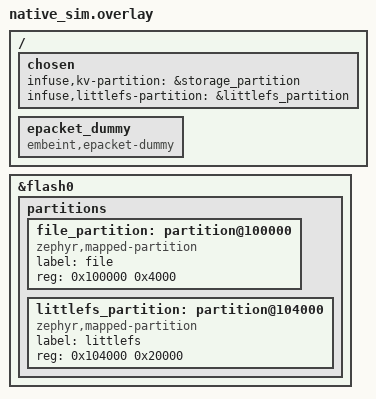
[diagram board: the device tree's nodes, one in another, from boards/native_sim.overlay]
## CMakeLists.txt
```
# SPDX-License-Identifier: Apache-2.0

cmake_minimum_required(VERSION 3.20.0)

# Infuse-IoT application
if(NOT infuse IN_LIST SNIPPET)
  set(SNIPPET infuse ${SNIPPET} CACHE STRING "" FORCE)
endif()

find_package(Zephyr REQUIRED HINTS $ENV{ZEPHYR_BASE})
project(rpc_commands_coap_download)

target_sources(app PRIVATE
  src/main.c
)
```

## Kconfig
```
config TEST_NATIVE_MOCK
	bool "Mock various file backends"
	default y if BOARD_NATIVE_SIM

config BT_CONTROLLER_MANAGER
	default y if TEST_NATIVE_MOCK

config TEST_COAP_SERVER
	string "CoAP server to download test resources from"
	default "coap.dev.infuse-iot.com"

config TEST_COAP_SERVER_PORT
	int "CoAP server DTLS port"
	default 5684

config TEST_COAP_SERVER_UNRESPONSIVE
	string "Server that resolves but never completes a DTLS handshake"
	default "www.google.com"

source "Kconfig.zephyr"
```

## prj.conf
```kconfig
CONFIG_ZTEST=y
CONFIG_INFUSE_SDK=y
CONFIG_INFUSE_CPATCH=y
CONFIG_INFUSE_DFU_HELPERS=y
CONFIG_INFUSE_RPC_LOG_LEVEL_DBG=y

CONFIG_NETWORKING=y

# Drop received packets to exercise the retry logic
CONFIG_INFUSE_COAP_TEST_PACKET_DROP_BITMASK=16389
```

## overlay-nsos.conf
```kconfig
CONFIG_ETH_NATIVE_POSIX=n
CONFIG_NET_DRIVERS=y
CONFIG_NET_SOCKETS=y
CONFIG_NET_SOCKETS_OFFLOAD=y
CONFIG_NET_NATIVE_OFFLOADED_SOCKETS=y
CONFIG_HEAP_MEM_POOL_SIZE=1024

CONFIG_NATIVE_SIM_SLOWDOWN_TO_REAL_TIME=y
```

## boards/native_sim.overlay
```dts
/ {
	chosen {
		infuse,kv-partition = &storage_partition;
		infuse,littlefs-partition = &littlefs_partition;
	};

	epacket_dummy: epacket_dummy {
		compatible = "embeint,epacket-dummy";
	};
};

&flash0 {
	partitions {
		file_partition: partition@100000 {
			compatible = "zephyr,mapped-partition";
			label = "file";
			reg = < 0x100000 0x4000 >;
		};
		littlefs_partition: partition@104000 {
			compatible = "zephyr,mapped-partition";
			label = "littlefs";
			reg = < 0x104000 0x20000 >;
		};
	};
};
```

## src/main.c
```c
/**
 * @file
 * @copyright 2024 Embeint Holdings Pty Ltd
 * @author Jordan Yates <jordan@embeint.com>
 *
 * SPDX-License-Identifier: FSL-1.1-ALv2
 */

#include <string.h>

#include <zephyr/ztest.h>
#include <zephyr/random/random.h>
#include <zephyr/storage/flash_map.h>
#include <zephyr/net/tls_credentials.h>
#include <zephyr/sys/crc.h>

#include <infuse/dfu/helpers.h>
#include <infuse/security.h>
#include <infuse/common_boot.h>
#include <infuse/types.h>
#include <infuse/rpc/types.h>
#include <infuse/rpc/errors.h>
#include <infuse/epacket/packet.h>
#include <infuse/epacket/interface/epacket_dummy.h>
#include <infuse/time/epoch.h>
#include <infuse/fs/littlefs.h>

#define COAP_SERVER              CONFIG_TEST_COAP_SERVER
#define COAP_PORT                CONFIG_TEST_COAP_SERVER_PORT
#define COAP_SERVER_UNRESPONSIVE CONFIG_TEST_COAP_SERVER_UNRESPONSIVE

struct rpc_coap_download_request_send {
	struct rpc_coap_download_request core;
	char resource[128];
} __packed;

struct rpc_coap_download_request_v2_send {
	struct rpc_coap_download_v2_request core;
	char resource[128];
} __packed;

struct rpc_coap_download_request_v3_send {
	struct rpc_coap_download_v3_request core;
	char resource[128];
} __packed;

#ifdef CONFIG_TLS_CREDENTIALS
/* Buffer must remain valid after `tls_credential_add` */
static char dtls_identity_buffer[16];
#endif /* CONFIG_TLS_CREDENTIALS */

#ifdef CONFIG_TEST_NATIVE_MOCK
static size_t bt_image_len;
static size_t bt_image_crc;
static uint32_t bt_fail_after;
static bool bt_in_progress;
static int bt_start_rc;
static int bt_finish_rc;

int bt_controller_manager_file_write_start(uint32_t *ctx, uint8_t action, size_t image_len)
{
	bt_image_len = image_len;
	bt_image_crc = 0;
	if (bt_start_rc == 0) {
		bt_in_progress = true;
	}
	return bt_start_rc;
}

int bt_controller_manager_file_write_next(uint32_t ctx, uint32_t image_offset,
					  const void *image_chunk, size_t chunk_len)
{
	zassert_equal(0, image_offset % sizeof(uint32_t));

	bt_image_crc = crc32_ieee_update(bt_image_crc, image_chunk, chunk_len);

	if (bt_fail_after > 0) {
		if (--bt_fail_after == 0) {
			return -EIO;
		}
	}
	return 0;
}

int bt_controller_manager_file_write_finish(uint32_t ctx, uint32_t *len, uint32_t *crc)
{
	*len = bt_image_len;
	*crc = bt_image_crc;
	bt_in_progress = false;
	return bt_finish_rc;
}

#endif /* CONFIG_TEST_NATIVE_MOCK */

static void send_download_command(uint32_t request_id, const char *server, uint16_t port,
				  uint16_t timeout, uint8_t action, char *resource, uint32_t len,
				  uint32_t crc)
{
	const struct device *epacket_dummy = DEVICE_DT_GET(DT_NODELABEL(epacket_dummy));
	struct epacket_dummy_frame header = {
		.type = INFUSE_RPC_CMD,
		.auth = EPACKET_AUTH_DEVICE,
		.flags = 0x0000,
	};
	struct rpc_coap_download_request_send params = {
		.core = {
			.header =
				{
					.request_id = request_id,
					.command_id = RPC_ID_COAP_DOWNLOAD,
				},
			.server_port = port,
			.block_timeout_ms = timeout,
			.action = action,
			.resource_crc = crc,
			.resource_len = len,
		}};

	strncpy(params.core.server_address, server, sizeof(params.core.server_address));
	params.core.server_port = port;
	strncpy(params.resource, resource, sizeof(params.resource));

	/* Push command at RPC server */
	epacket_dummy_receive(epacket_dummy, &header, &params, sizeof(params));
}

static void send_download_v2_command(uint32_t request_id, const char *server, uint16_t port,
				     uint16_t timeout, uint8_t action, char *resource, uint32_t len,
				     uint32_t crc, uint16_t block_size)
{
	const struct device *epacket_dummy = DEVICE_DT_GET(DT_NODELABEL(epacket_dummy));
	struct epacket_dummy_frame header = {
		.type = INFUSE_RPC_CMD,
		.auth = EPACKET_AUTH_DEVICE,
		.flags = 0x0000,
	};
	struct rpc_coap_download_request_v2_send params = {
		.core = {
			.header =
				{
					.request_id = request_id,
					.command_id = RPC_ID_COAP_DOWNLOAD_V2,
				},
			.server_port = port,
			.block_timeout_ms = timeout,
			.block_size = block_size,
			.action = action,
			.resource_crc = crc,
			.resource_len = len,
		}};

	strncpy(params.core.server_address, server, sizeof(params.core.server_address));
	params.core.server_port = port;
	strncpy(params.resource, resource, sizeof(params.resource));

	/* Push command at RPC server */
	epacket_dummy_receive(epacket_dummy, &header, &params, sizeof(params));
}

static void send_download_v3_command(uint32_t request_id, const char *server, uint16_t port,
				     uint16_t timeout, uint8_t action, uint8_t folder,
				     uint32_t filename, uint32_t identifier, char *resource,
				     uint32_t len, uint32_t crc, uint16_t block_size)
{
	const struct device *epacket_dummy = DEVICE_DT_GET(DT_NODELABEL(epacket_dummy));
	struct epacket_dummy_frame header = {
		.type = INFUSE_RPC_CMD,
		.auth = EPACKET_AUTH_DEVICE,
		.flags = 0x0000,
	};
	struct rpc_coap_download_request_v3_send params = {
		.core = {
			.header =
				{
					.request_id = request_id,
					.command_id = RPC_ID_COAP_DOWNLOAD_V3,
				},
			.server_port = port,
			.block_timeout_ms = timeout,
			.block_size = block_size,
			.action = action,
			.folder = folder,
			.filename = filename,
			.identifier = identifier,
			.resource_crc = crc,
			.resource_len = len,
		}};

	strncpy(params.core.server_address, server, sizeof(params.core.server_address));
	params.core.server_port = port;
	strncpy(params.resource, resource, sizeof(params.resource));

	/* Push command at RPC server */
	epacket_dummy_receive(epacket_dummy, &header, &params, sizeof(params));
}

static void expect_coap_download_response(uint32_t request_id, int16_t rc, uint32_t len,
					  uint32_t crc)
{
	struct k_fifo *response_queue = epacket_dummmy_transmit_fifo_get();
	struct rpc_coap_download_response *response;
	struct net_buf *rsp;

	zassert_not_null(response_queue);

	/* Response was sent */
	rsp = k_fifo_get(response_queue, K_SECONDS(30));
	zassert_not_null(rsp);
	response = (void *)(rsp->data + sizeof(struct epacket_dummy_frame));

	/* Parameters match what we expect */
	zassert_equal(request_id, response->header.request_id);
	zassert_equal(rc, response->header.return_code);
	zassert_equal(len, response->resource_len);
	zassert_equal(crc, response->resource_crc);

	/* Free the response */
	net_buf_unref(rsp);
}

static void send_download_v3_raw(uint32_t request_id, bool terminate_server,
				 bool terminate_resource)
{
	const struct device *epacket_dummy = DEVICE_DT_GET(DT_NODELABEL(epacket_dummy));
	struct epacket_dummy_frame header = {
		.type = INFUSE_RPC_CMD,
		.auth = EPACKET_AUTH_DEVICE,
		.flags = 0x0000,
	};
	struct rpc_coap_download_request_v3_send params = {
		.core = {
			.header =
				{
					.request_id = request_id,
					.command_id = RPC_ID_COAP_DOWNLOAD_V3,
				},
			.server_port = COAP_PORT,
			.action = RPC_ENUM_FILE_ACTION_DISCARD,
			.resource_crc = UINT32_MAX,
			.resource_len = UINT32_MAX,
		}};
	size_t resource_len;

	if (terminate_server) {
		strcpy(params.core.server_address, COAP_SERVER);
	} else {
		memset(params.core.server_address, 's', sizeof(params.core.server_address));
	}

	if (terminate_resource) {
		strcpy(params.resource, "file/small_file");
		resource_len = strlen(params.resource) + 1;
	} else {
		memset(params.resource, 'r', sizeof(params.resource));
		resource_len = sizeof(params.resource);
	}

	epacket_dummy_receive(epacket_dummy, &header, &params, sizeof(params.core) + resource_len);
}

ZTEST(rpc_command_coap_download, test_download_invalid_strings)
{
	send_download_v3_raw(0x5000, false, true);
	expect_coap_download_response(0x5000, INFUSE_RPC_ERROR_MALFORMED_REQUEST, 0, 0);

	send_download_v3_raw(0x5001, true, false);
	expect_coap_download_response(0x5001, INFUSE_RPC_ERROR_MALFORMED_REQUEST, 0, 0);
}

ZTEST(rpc_command_coap_download, test_download_invalid)
{
	/* Bad actions */
	send_download_command(1, COAP_SERVER, COAP_PORT, 0, 5, "file/small", UINT32_MAX,
			      UINT32_MAX);
	expect_coap_download_response(1, INFUSE_RPC_ERROR_UNSUPPORTED_REQUEST, 0, 0);
	send_download_command(2, COAP_SERVER, COAP_PORT, 0, 5, "file/small", UINT32_MAX,
			      UINT32_MAX);
	expect_coap_download_response(2, INFUSE_RPC_ERROR_UNSUPPORTED_REQUEST, 0, 0);

	/* Bad file */
	send_download_command(5, COAP_SERVER, COAP_PORT, 0, RPC_ENUM_FILE_ACTION_DISCARD,
			      "file/doesn't-exist", UINT32_MAX, UINT32_MAX);
	expect_coap_download_response(5, INFUSE_RPC_ERROR_COAP_DOWNLOAD_FAILED, 0, 0);

	/* Bad server */
	send_download_command(3, "does-not-exist.invalid", COAP_PORT, 0,
			      RPC_ENUM_FILE_ACTION_DISCARD, "file/small", UINT32_MAX, UINT32_MAX);
	expect_coap_download_response(3, INFUSE_RPC_ERROR_DNS_QUERY_FAILED, 0, 0);

	/* Bad port */
	send_download_command(4, COAP_SERVER, 1000, 0, RPC_ENUM_FILE_ACTION_DISCARD, "file/small",
			      UINT32_MAX, UINT32_MAX);
	expect_coap_download_response(4, INFUSE_RPC_ERROR_SOCKET_CONNECT_FAILED, 0, 0);

	/* Connect failure */
	send_download_command(6, COAP_SERVER_UNRESPONSIVE, COAP_PORT, 0,
			      RPC_ENUM_FILE_ACTION_DISCARD, "file/small", UINT32_MAX, UINT32_MAX);
	expect_coap_download_response(6, INFUSE_RPC_ERROR_SOCKET_CONNECT_FAILED, 0, 0);

	/* Tiny timeout */
	send_download_command(20, COAP_SERVER, COAP_PORT, 1, RPC_ENUM_FILE_ACTION_DISCARD,
			      "file/small_file", UINT32_MAX, UINT32_MAX);
	expect_coap_download_response(20, INFUSE_RPC_ERROR_COAP_DOWNLOAD_FAILED, 0, 0);

#ifdef CONFIG_TLS_CREDENTIALS
	sec_tag_t tag = infuse_security_coap_dtls_tag();
	size_t cred_len;

	/* Cache the credential */
	cred_len = sizeof(dtls_identity_buffer);
	zassert_equal(
		0, tls_credential_get(tag, TLS_CREDENTIAL_PSK_ID, dtls_identity_buffer, &cred_len));
	zassert_equal(sizeof(dtls_identity_buffer), cred_len);

	/* Delete the credential */
	zassert_equal(0, tls_credential_delete(tag, TLS_CREDENTIAL_PSK_ID));

	/* Basic discard download */
	send_download_command(100, COAP_SERVER, COAP_PORT, 0, RPC_ENUM_FILE_ACTION_DISCARD,
			      "file/small_file", UINT32_MAX, UINT32_MAX);
	expect_coap_download_response(100, INFUSE_RPC_ERROR_SOCKET_CONFIG_FAILED, 0, 0);

	/* Re-add the credential */
	zassert_equal(0, tls_credential_add(tag, TLS_CREDENTIAL_PSK_ID, dtls_identity_buffer,
					    sizeof(dtls_identity_buffer)));
#endif /* CONFIG_TLS_CREDENTIALS */

	/* Everything works after all the failures */
	send_download_command(10, COAP_SERVER, COAP_PORT, 0, RPC_ENUM_FILE_ACTION_DISCARD,
			      "file/small_file", UINT32_MAX, UINT32_MAX);
	expect_coap_download_response(10, 0, 12, 0xb5289bef);
}

ZTEST(rpc_command_coap_download, test_download)
{
	const struct flash_area *fa;

	/* Ensure consistent starting point */
	flash_area_open(PARTITION_ID(slot1_partition), &fa);
	flash_area_erase(fa, 0, fa->fa_size);
	flash_area_close(fa);

	/* Basic discard download */
	send_download_command(10, COAP_SERVER, COAP_PORT, 0, RPC_ENUM_FILE_ACTION_DISCARD,
			      "file/small_file", UINT32_MAX, UINT32_MAX);
	expect_coap_download_response(10, 0, 12, 0xb5289bef);

	/* Larger discard download */
	send_download_command(10, COAP_SERVER, COAP_PORT, 0, RPC_ENUM_FILE_ACTION_DISCARD,
			      "file/med_file", UINT32_MAX, UINT32_MAX);
	expect_coap_download_response(10, 0, 10030, 0x9919d24e);

	/* Small DFU download of unknown length and size */
	send_download_command(20, COAP_SERVER, COAP_PORT, 0, RPC_ENUM_FILE_ACTION_APP_IMG,
			      "file/small_file", UINT32_MAX, UINT32_MAX);
	expect_coap_download_response(20, 0, 12, 0xb5289bef);

	/* Download file contents for DFU */
	send_download_command(10, COAP_SERVER, COAP_PORT, 0, RPC_ENUM_FILE_ACTION_APP_IMG,
			      "file/med_file", 10030, 0x9919d24e);
	expect_coap_download_response(10, 0, 10030, 0x9919d24e);

	/* Second time should detect file has already been downloaded */
	send_download_command(11, COAP_SERVER, COAP_PORT, 0, RPC_ENUM_FILE_ACTION_APP_IMG,
			      "file/med_file", 10030, 0x9919d24e);
	expect_coap_download_response(11, 0, 0, 0x9919d24e);

	/* But if CRC not provided, file is downloaded again */
	send_download_command(12, COAP_SERVER, COAP_PORT, 0, RPC_ENUM_FILE_ACTION_APP_IMG,
			      "file/med_file", 10030, UINT32_MAX);
	expect_coap_download_response(12, 0, 10030, 0x9919d24e);

	/* DFU requested too large */
	send_download_command(20, COAP_SERVER, COAP_PORT, 0, RPC_ENUM_FILE_ACTION_APP_IMG,
			      "file/small_file", UINT32_MAX / 2, UINT32_MAX);
	expect_coap_download_response(20, INFUSE_RPC_ERROR_FLASH_DATA_TOO_LARGE, 0, 0);

	/* Balanced call count */
	zassert_equal(0, infuse_dfu_write_erase_call_count());
}

ZTEST(rpc_command_coap_download, test_download_v2)
{
	/* Basic discard download */
	send_download_v2_command(48, COAP_SERVER, COAP_PORT, 0, RPC_ENUM_FILE_ACTION_DISCARD,
				 "file/small_file", UINT32_MAX, UINT32_MAX, 0);
	expect_coap_download_response(48, 0, 12, 0xb5289bef);

	/* Larger discard download */
	send_download_v2_command(50, COAP_SERVER, COAP_PORT, 0, RPC_ENUM_FILE_ACTION_DISCARD,
				 "file/med_file", UINT32_MAX, UINT32_MAX, 1024);
	expect_coap_download_response(50, 0, 10030, 0x9919d24e);
}

ZTEST(rpc_command_coap_download, test_download_v3)
{
	struct infuse_littlefs_metadata meta;
	int rc;

	/* Basic discard download */
	send_download_v3_command(200, COAP_SERVER, COAP_PORT, 0, RPC_ENUM_FILE_ACTION_DISCARD, 0, 0,
				 0, "file/small_file", UINT32_MAX, UINT32_MAX, 0);
	expect_coap_download_response(200, 0, 12, 0xb5289bef);

	/* Larger discard download */
	send_download_v3_command(201, COAP_SERVER, COAP_PORT, 0, RPC_ENUM_FILE_ACTION_DISCARD, 0, 0,
				 0, "file/med_file", UINT32_MAX, UINT32_MAX, 1024);
	expect_coap_download_response(201, 0, 10030, 0x9919d24e);

	/* Write an algorithm */
	send_download_v3_command(202, COAP_SERVER, COAP_PORT, 0,
				 RPC_ENUM_FILE_ACTION_WRITE_LITTLEFS, INFUSE_LFS_FOLDER_ALGORITHMS,
				 0, 1000, "file/small_file", 12, 0xb5289bef, 512);
	expect_coap_download_response(202, 0, 12, 0xb5289bef);
	rc = infuse_littlefs_file_size(INFUSE_LFS_FOLDER_ALGORITHMS, 0);
	zassert_equal(12, rc);
	rc = infuse_littlefs_file_metadata(INFUSE_LFS_FOLDER_ALGORITHMS, 0, &meta);
	zassert_equal(0, rc);
	zassert_equal(1000, meta.identifier);
	zassert_equal(0xb5289bef, meta.crc);

	/* Same algorithm again doesn't download data */
	send_download_v3_command(203, COAP_SERVER, COAP_PORT, 0,
				 RPC_ENUM_FILE_ACTION_WRITE_LITTLEFS, INFUSE_LFS_FOLDER_ALGORITHMS,
				 0, 1000, "file/small_file", 12, 0xb5289bef, 512);
	expect_coap_download_response(203, 0, 0, 0xb5289bef);
	rc = infuse_littlefs_file_size(INFUSE_LFS_FOLDER_ALGORITHMS, 0);
	zassert_equal(12, rc);
	rc = infuse_littlefs_file_metadata(INFUSE_LFS_FOLDER_ALGORITHMS, 0, &meta);
	zassert_equal(0, rc);
	zassert_equal(1000, meta.identifier);
	zassert_equal(0xb5289bef, meta.crc);

	/* Different algorithm to same slot overwrites */
	send_download_v3_command(204, COAP_SERVER, COAP_PORT, 0,
				 RPC_ENUM_FILE_ACTION_WRITE_LITTLEFS, INFUSE_LFS_FOLDER_ALGORITHMS,
				 0, 1001, "file/med_file", 10030, 0x9919d24e, 1024);
	expect_coap_download_response(204, 0, 10030, 0x9919d24e);
	rc = infuse_littlefs_file_size(INFUSE_LFS_FOLDER_ALGORITHMS, 0);
	zassert_equal(10030, rc);
	rc = infuse_littlefs_file_metadata(INFUSE_LFS_FOLDER_ALGORITHMS, 0, &meta);
	zassert_equal(0, rc);
	zassert_equal(1001, meta.identifier);
	zassert_equal(0x9919d24e, meta.crc);

	/* Different algorithm */
	send_download_v3_command(205, COAP_SERVER, COAP_PORT, 0,
				 RPC_ENUM_FILE_ACTION_WRITE_LITTLEFS, INFUSE_LFS_FOLDER_ALGORITHMS,
				 5, 0x200, "file/small_file", 12, 0xb5289bef, 0);
	expect_coap_download_response(205, 0, 12, 0xb5289bef);
	rc = infuse_littlefs_file_size(INFUSE_LFS_FOLDER_ALGORITHMS, 5);
	zassert_equal(12, rc);
	rc = infuse_littlefs_file_metadata(INFUSE_LFS_FOLDER_ALGORITHMS, 5, &meta);
	zassert_equal(0, rc);
	zassert_equal(0x200, meta.identifier);
	zassert_equal(0xb5289bef, meta.crc);

	/* Non-algorithm folder */
	send_download_v3_command(206, COAP_SERVER, COAP_PORT, 0,
				 RPC_ENUM_FILE_ACTION_WRITE_LITTLEFS, INFUSE_LFS_FOLDER_COPY, 100,
				 0x201, "file/small_file", 12, 0xb5289bef, 0);
	expect_coap_download_response(206, 0, 12, 0xb5289bef);
	rc = infuse_littlefs_file_size(INFUSE_LFS_FOLDER_COPY, 100);
	zassert_equal(12, rc);
	rc = infuse_littlefs_file_metadata(INFUSE_LFS_FOLDER_COPY, 100, &meta);
	zassert_equal(0, rc);
	zassert_equal(0x201, meta.identifier);
	zassert_equal(0xb5289bef, meta.crc);
}

ZTEST(rpc_command_coap_download, test_download_v3_error_cleanup)
{
	struct infuse_littlefs_metadata meta;
	int rc;

	/* Download request that will immediately timeout, file should be closed, but not deleted */
	send_download_v3_command(20, COAP_SERVER, COAP_PORT, 1, RPC_ENUM_FILE_ACTION_WRITE_LITTLEFS,
				 INFUSE_LFS_FOLDER_ALGORITHMS, 0, 1001, "file/med_file", 10030,
				 0x9919d24e, 1024);
	expect_coap_download_response(20, INFUSE_RPC_ERROR_COAP_DOWNLOAD_FAILED, 0, 0);
	rc = infuse_littlefs_file_size(INFUSE_LFS_FOLDER_ALGORITHMS, 0);
	zassert_equal(0, rc);
	rc = infuse_littlefs_file_metadata(INFUSE_LFS_FOLDER_ALGORITHMS, 0, &meta);
	zassert_equal(0, rc);
	zassert_equal(1001, meta.identifier);
	zassert_equal(0, meta.crc);
}

ZTEST(rpc_command_coap_download, test_download_littlefs_reject)
{
	/* ACTION_WRITE_LITTLEFS should be rejected for legacy RPCs */
	send_download_command(99, COAP_SERVER, COAP_PORT, 0, RPC_ENUM_FILE_ACTION_WRITE_LITTLEFS,
			      "file/small_file", UINT32_MAX, UINT32_MAX);
	expect_coap_download_response(99, INFUSE_RPC_ERROR_UNSUPPORTED_REQUEST, 0, 0);

	send_download_v2_command(100, COAP_SERVER, COAP_PORT, 0,
				 RPC_ENUM_FILE_ACTION_WRITE_LITTLEFS, "file/small_file", UINT32_MAX,
				 UINT32_MAX, 0);
	expect_coap_download_response(100, INFUSE_RPC_ERROR_UNSUPPORTED_REQUEST, 0, 0);
}

ZTEST(rpc_command_coap_download, test_download_bt_ctlr)
{
#ifdef CONFIG_TEST_NATIVE_MOCK
	send_download_command(15, COAP_SERVER, COAP_PORT, 0, RPC_ENUM_FILE_ACTION_BT_CTLR_IMG,
			      "file/med_file", 10030, UINT32_MAX);
	expect_coap_download_response(15, 0, 10030, 0x9919d24e);
	zassert_false(bt_in_progress);

	bt_start_rc = -EIO;
	send_download_command(20, COAP_SERVER, COAP_PORT, 0, RPC_ENUM_FILE_ACTION_BT_CTLR_IMG,
			      "file/med_file", 10030, UINT32_MAX);
	expect_coap_download_response(20, INFUSE_RPC_ERROR_BT_COMMAND_QUEUE_FAILED, 0, 0);
	zassert_false(bt_in_progress);
	bt_start_rc = 0;

	bt_fail_after = 10;
	send_download_command(16, COAP_SERVER, COAP_PORT, 0, RPC_ENUM_FILE_ACTION_BT_CTLR_IMG,
			      "file/med_file", 10030, UINT32_MAX);
	expect_coap_download_response(16, INFUSE_RPC_ERROR_BT_REMOTE_ERROR, 0, 0);
	zassert_false(bt_in_progress);

	bt_finish_rc = -EINVAL;
	send_download_command(30, COAP_SERVER, COAP_PORT, 0, RPC_ENUM_FILE_ACTION_BT_CTLR_IMG,
			      "file/med_file", 10030, UINT32_MAX);
	expect_coap_download_response(30, INFUSE_RPC_ERROR_BT_REMOTE_ERROR, 10030, 0x9919d24e);
	zassert_false(bt_in_progress);
	bt_finish_rc = 0;

	send_download_command(17, COAP_SERVER, COAP_PORT, 0, RPC_ENUM_FILE_ACTION_BT_CTLR_IMG,
			      "file/med_file", 10030, UINT32_MAX);
	expect_coap_download_response(17, 0, 10030, 0x9919d24e);
	zassert_false(bt_in_progress);
	zassert_false(bt_in_progress);
#endif /* CONFIG_TEST_NATIVE_MOCK */
}

static void flash_area_copy_wrapped(uint8_t partition_dst, uint8_t partition_src, uint32_t len)
{
	const struct flash_area *fa_dst, *fa_src;
	uint8_t buffer[128];

	zassert_equal(0, flash_area_open(partition_dst, &fa_dst));
	zassert_equal(0, flash_area_open(partition_src, &fa_src));

	zassert_equal(0, flash_area_erase(fa_dst, 0, fa_dst->fa_size));
	zassert_equal(
		0, flash_area_copy(fa_src, 0, fa_dst, 0, fa_dst->fa_size, buffer, sizeof(buffer)));

	flash_area_close(fa_dst);
	flash_area_close(fa_src);
}

ZTEST(rpc_command_coap_download, test_download_cpatch)
{
	const struct flash_area *fa_dst;

	/* Clear any previous state in the original image slot */
	zassert_equal(0, flash_area_open(PARTITION_ID(slot0_partition), &fa_dst));
	zassert_equal(0, flash_area_erase(fa_dst, 0, fa_dst->fa_size));
	flash_area_close(fa_dst);

	/* Attempting to run the patch file initially should fail due to invalid original data */
	send_download_command(20, COAP_SERVER, COAP_PORT, 0, RPC_ENUM_FILE_ACTION_APP_CPATCH,
			      "file/hello_world-validate", 333, UINT32_MAX);
	expect_coap_download_response(20, INFUSE_RPC_ERROR_PATCH_VALIDATE_FAILED, 333, 0x8451810D);

	/* Download the base image into partition1 */
	send_download_command(21, COAP_SERVER, COAP_PORT, 0, RPC_ENUM_FILE_ACTION_APP_IMG,
			      "file/hello_world", 18940, UINT32_MAX);
	expect_coap_download_response(21, 0, 18940, 0xE58FF061);

	/* Copy the base image into partition0 */
	flash_area_copy_wrapped(PARTITION_ID(slot0_partition), PARTITION_ID(slot1_partition),
				18940);

	/* Patch file should download and apply cleanly now */
	send_download_command(22, COAP_SERVER, COAP_PORT, 0, RPC_ENUM_FILE_ACTION_APP_CPATCH,
			      "file/hello_world-validate", 333, UINT32_MAX);
	expect_coap_download_response(22, 0, 333, 0x8451810D);

	/* Balanced call count */
	zassert_equal(0, infuse_dfu_write_erase_call_count());
}

void coap_download_setup(void *ctx)
{
	(void)infuse_littfs_format();
	(void)infuse_littlefs_init();
}

ZTEST_SUITE(rpc_command_coap_download, NULL, NULL, coap_download_setup, NULL, NULL);
```
